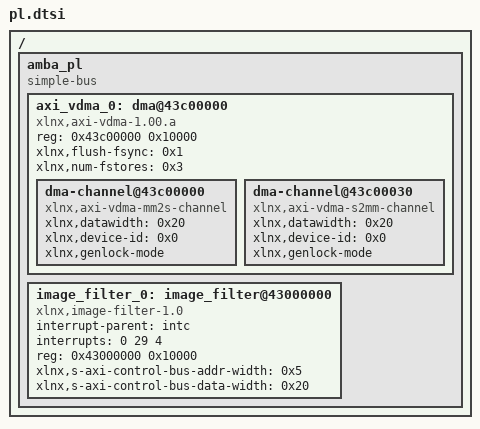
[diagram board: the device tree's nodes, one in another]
/*
 * CAUTION: This file is automatically generated by Xilinx.
 * Version: HSI 
 * Today is: Thu Jun 23 18:16:10 2016
*/


/ {
	amba_pl: amba_pl {
		#address-cells = <1>;
		#size-cells = <1>;
		compatible = "simple-bus";
		ranges ;
		axi_vdma_0: dma@43c00000 {
			#dma-cells = <1>;
			compatible = "xlnx,axi-vdma-1.00.a";
			reg = <0x43c00000 0x10000>;
			xlnx,flush-fsync = <0x1>;
			xlnx,num-fstores = <0x3>;
			dma-channel@43c00000 {
				compatible = "xlnx,axi-vdma-mm2s-channel";
				xlnx,datawidth = <0x20>;
				xlnx,device-id = <0x0>;
				xlnx,genlock-mode ;
			};
			dma-channel@43c00030 {
				compatible = "xlnx,axi-vdma-s2mm-channel";
				xlnx,datawidth = <0x20>;
				xlnx,device-id = <0x0>;
				xlnx,genlock-mode ;
			};
		};
		image_filter_0: image_filter@43000000 {
			compatible = "xlnx,image-filter-1.0";
			interrupt-parent = <&intc>;
			interrupts = <0 29 4>;
			reg = <0x43000000 0x10000>;
			xlnx,s-axi-control-bus-addr-width = <0x5>;
			xlnx,s-axi-control-bus-data-width = <0x20>;
		};
	};
};
